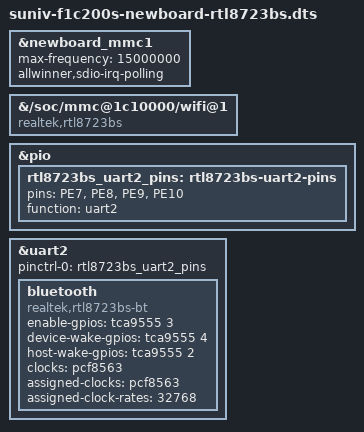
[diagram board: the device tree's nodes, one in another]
// SPDX-License-Identifier: (GPL-2.0+ OR X11)
#include "suniv-f1c200s-newboard-rtl8723ds.dts"

&newboard_mmc1 {
    max-frequency = <15000000>;
    allwinner,sdio-irq-polling;
};

/* Shared host wiring, but the SDIO device is RTL8723B, not RTL8723D. */
&{/soc/mmc@1c10000/wifi@1} {
    compatible = "realtek,rtl8723bs";
};

&pio {
    rtl8723bs_uart2_pins: rtl8723bs-uart2-pins {
        pins = "PE7", "PE8", "PE9", "PE10";
        function = "uart2";
    };
};

&uart2 {
    pinctrl-names = "default";
    pinctrl-0 = <&rtl8723bs_uart2_pins>;
    status = "okay";

    bluetooth {
        compatible = "realtek,rtl8723bs-bt";
        enable-gpios = <&tca9555 3 GPIO_ACTIVE_HIGH>;
        device-wake-gpios = <&tca9555 4 GPIO_ACTIVE_HIGH>;
        host-wake-gpios = <&tca9555 2 GPIO_ACTIVE_HIGH>;
        clocks = <&pcf8563>;
        clock-names = "lpo";
        assigned-clocks = <&pcf8563>;
        assigned-clock-rates = <32768>;
    };
};
